AUTOSAR XML (schema 00046)
package /ComponentTypes
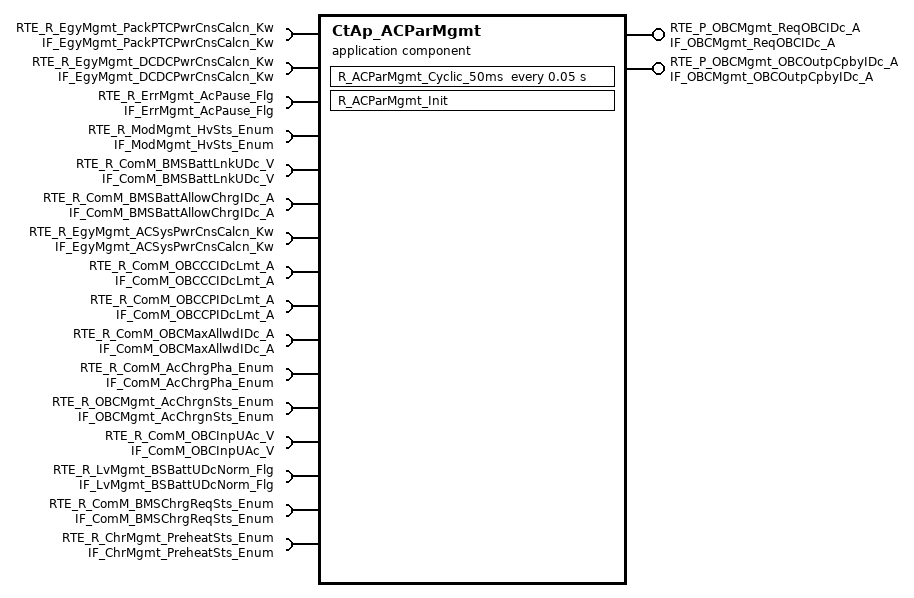
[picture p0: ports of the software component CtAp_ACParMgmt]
  application sw component type CtAp_ACParMgmt
    4 x require port:
      RTE_R_EgyMgmt_PackPTCPwrCnsCalcn_Kw: nonqueued-receiver-com-spec{data-element=tec_EgyMgmt_PackPTCPwrCnsCalcn_Kw, filter=data-filter-type=ALWAYS, init-value=0}, required-interface=IF_EgyMgmt_PackPTCPwrCnsCalcn_Kw
      RTE_R_EgyMgmt_DCDCPwrCnsCalcn_Kw: nonqueued-receiver-com-spec{data-element=tec_EgyMgmt_DCDCPwrCnsCalcn_Kw, filter=data-filter-type=ALWAYS, init-value=0}, required-interface=IF_EgyMgmt_DCDCPwrCnsCalcn_Kw
      RTE_R_ErrMgmt_AcPause_Flg: nonqueued-receiver-com-spec{data-element=tec_ErrMgmt_AcPause_Flg, filter=data-filter-type=ALWAYS, init-value=0}, required-interface=IF_ErrMgmt_AcPause_Flg
      RTE_R_ModMgmt_HvSts_Enum: nonqueued-receiver-com-spec{data-element=tec_ModMgmt_HvSts_Enum, filter=data-filter-type=ALWAYS, init-value=0}, required-interface=IF_ModMgmt_HvSts_Enum
    provide port RTE_P_OBCMgmt_ReqOBCIDc_A: nonqueued-sender-com-spec{data-element=tec_OBCMgmt_ReqOBCIDc_A, init-value=0}, provided-interface=IF_OBCMgmt_ReqOBCIDc_A
    6 x require port:
      RTE_R_ComM_BMSBattLnkUDc_V: nonqueued-receiver-com-spec{data-element=tec_ComM_BMSBattLnkUDc_V, filter=data-filter-type=ALWAYS, init-value=0}, required-interface=IF_ComM_BMSBattLnkUDc_V
      RTE_R_ComM_BMSBattAllowChrgIDc_A: nonqueued-receiver-com-spec{data-element=tec_ComM_BMSBattAllowChrgIDc_A, filter=data-filter-type=ALWAYS, init-value=0}, required-interface=IF_ComM_BMSBattAllowChrgIDc_A
      RTE_R_EgyMgmt_ACSysPwrCnsCalcn_Kw: nonqueued-receiver-com-spec{data-element=tec_EgyMgmt_ACSysPwrCnsCalcn_Kw, filter=data-filter-type=ALWAYS, init-value=0}, required-interface=IF_EgyMgmt_ACSysPwrCnsCalcn_Kw
      RTE_R_ComM_OBCCCIDcLmt_A: nonqueued-receiver-com-spec{data-element=tec_ComM_OBCCCIDcLmt_A, filter=data-filter-type=ALWAYS, init-value=0}, required-interface=IF_ComM_OBCCCIDcLmt_A
      RTE_R_ComM_OBCCPIDcLmt_A: nonqueued-receiver-com-spec{data-element=tec_ComM_OBCCPIDcLmt_A, filter=data-filter-type=ALWAYS, init-value=0}, required-interface=IF_ComM_OBCCPIDcLmt_A
      RTE_R_ComM_OBCMaxAllwdIDc_A: nonqueued-receiver-com-spec{data-element=tec_ComM_OBCMaxAllwdIDc_A, filter=data-filter-type=ALWAYS, init-value=0}, required-interface=IF_ComM_OBCMaxAllwdIDc_A
    provide port RTE_P_OBCMgmt_OBCOutpCpbyIDc_A: nonqueued-sender-com-spec{data-element=tec_OBCMgmt_OBCOutpCpbyIDc_A, init-value=0}, provided-interface=IF_OBCMgmt_OBCOutpCpbyIDc_A
    6 x require port:
      RTE_R_ComM_AcChrgPha_Enum: nonqueued-receiver-com-spec{data-element=tec_ComM_AcChrgPha_Enum, filter=data-filter-type=ALWAYS, init-value=0}, required-interface=IF_ComM_AcChrgPha_Enum
      RTE_R_OBCMgmt_AcChrgnSts_Enum: nonqueued-receiver-com-spec{data-element=tec_OBCMgmt_AcChrgnSts_Enum, filter=data-filter-type=ALWAYS, init-value=0}, required-interface=IF_OBCMgmt_AcChrgnSts_Enum
      RTE_R_ComM_OBCInpUAc_V: nonqueued-receiver-com-spec{data-element=tec_ComM_OBCInpUAc_V, filter=data-filter-type=ALWAYS, init-value=0}, required-interface=IF_ComM_OBCInpUAc_V
      RTE_R_LvMgmt_BSBattUDcNorm_Flg: nonqueued-receiver-com-spec{data-element=tec_LvMgmt_BSBattUDcNorm_Flg, filter=data-filter-type=ALWAYS, init-value=0}, required-interface=IF_LvMgmt_BSBattUDcNorm_Flg
      RTE_R_ComM_BMSChrgReqSts_Enum: nonqueued-receiver-com-spec{data-element=tec_ComM_BMSChrgReqSts_Enum, filter=data-filter-type=ALWAYS, init-value=0}, required-interface=IF_ComM_BMSChrgReqSts_Enum
      RTE_R_ChrMgmt_PreheatSts_Enum: nonqueued-receiver-com-spec{data-element=tec_ChrMgmt_PreheatSts_Enum, filter=data-filter-type=ALWAYS, init-value=0}, required-interface=IF_ChrMgmt_PreheatSts_Enum
    behavior CtAp_ACParMgmt_InternalBehavior
      timing event TMT_R_ACParMgmt_Cyclic_50ms: start-on-event=R_ACParMgmt_Cyclic_50ms, period=0.05
      init event CtAp_ACParMgmt_InitEvent: start-on-event=R_ACParMgmt_Init
      runnable R_ACParMgmt_Cyclic_50ms
        data-receive-point-by-arguments:
          16 x access:
            REC_RTE_R_ComM_AcChrgPha_Enum_tec_ComM_AcChrgPha_Enum: accessed-variable=RTE_R_ComM_AcChrgPha_Enum.tec_ComM_AcChrgPha_Enum
            REC_RTE_R_ComM_BMSBattAllowChrgIDc_A_tec_ComM_BMSBattAllowChrgIDc_A: accessed-variable=RTE_R_ComM_BMSBattAllowChrgIDc_A.tec_ComM_BMSBattAllowChrgIDc_A
            REC_RTE_R_ComM_BMSBattLnkUDc_V_tec_ComM_BMSBattLnkUDc_V: accessed-variable=RTE_R_ComM_BMSBattLnkUDc_V.tec_ComM_BMSBattLnkUDc_V
            REC_RTE_R_ComM_OBCCCIDcLmt_A_tec_ComM_OBCCCIDcLmt_A: accessed-variable=RTE_R_ComM_OBCCCIDcLmt_A.tec_ComM_OBCCCIDcLmt_A
            REC_RTE_R_ComM_OBCCPIDcLmt_A_tec_ComM_OBCCPIDcLmt_A: accessed-variable=RTE_R_ComM_OBCCPIDcLmt_A.tec_ComM_OBCCPIDcLmt_A
            REC_RTE_R_ComM_OBCInpUAc_V_tec_ComM_OBCInpUAc_V: accessed-variable=RTE_R_ComM_OBCInpUAc_V.tec_ComM_OBCInpUAc_V
            REC_RTE_R_ComM_OBCMaxAllwdIDc_A_tec_ComM_OBCMaxAllwdIDc_A: accessed-variable=RTE_R_ComM_OBCMaxAllwdIDc_A.tec_ComM_OBCMaxAllwdIDc_A
            REC_RTE_R_EgyMgmt_ACSysPwrCnsCalcn_Kw_tec_EgyMgmt_ACSysPwrCnsCalcn_Kw: accessed-variable=RTE_R_EgyMgmt_ACSysPwrCnsCalcn_Kw.tec_EgyMgmt_ACSysPwrCnsCalcn_Kw
            REC_RTE_R_EgyMgmt_DCDCPwrCnsCalcn_Kw_tec_EgyMgmt_DCDCPwrCnsCalcn_Kw: accessed-variable=RTE_R_EgyMgmt_DCDCPwrCnsCalcn_Kw.tec_EgyMgmt_DCDCPwrCnsCalcn_Kw
            REC_RTE_R_EgyMgmt_PackPTCPwrCnsCalcn_Kw_tec_EgyMgmt_PackPTCPwrCnsCalcn_Kw: accessed-variable=RTE_R_EgyMgmt_PackPTCPwrCnsCalcn_Kw.tec_EgyMgmt_PackPTCPwrCnsCalcn_Kw
            REC_RTE_R_ErrMgmt_AcPause_Flg_tec_ErrMgmt_AcPause_Flg: accessed-variable=RTE_R_ErrMgmt_AcPause_Flg.tec_ErrMgmt_AcPause_Flg
            REC_RTE_R_ModMgmt_HvSts_Enum_tec_ModMgmt_HvSts_Enum: accessed-variable=RTE_R_ModMgmt_HvSts_Enum.tec_ModMgmt_HvSts_Enum
            REC_RTE_R_OBCMgmt_AcChrgnSts_Enum_tec_OBCMgmt_AcChrgnSts_Enum: accessed-variable=RTE_R_OBCMgmt_AcChrgnSts_Enum.tec_OBCMgmt_AcChrgnSts_Enum
            REC_RTE_R_ComM_BMSChrgReqSts_Enum_tec_ComM_BMSChrgReqSts_Enum: accessed-variable=RTE_R_ComM_BMSChrgReqSts_Enum.tec_ComM_BMSChrgReqSts_Enum
            REC_RTE_R_LvMgmt_BSBattUDcNorm_Flg_tec_LvMgmt_BSBattUDcNorm_Flg: accessed-variable=RTE_R_LvMgmt_BSBattUDcNorm_Flg.tec_LvMgmt_BSBattUDcNorm_Flg
            REC_RTE_R_ChrMgmt_PreheatSts_Enum_tec_ChrMgmt_PreheatSts_Enum: accessed-variable=RTE_R_ChrMgmt_PreheatSts_Enum.tec_ChrMgmt_PreheatSts_Enum
        data-send-points:
          access SEND_RTE_P_OBCMgmt_OBCOutpCpbyIDc_A_tec_OBCMgmt_OBCOutpCpbyIDc_A: accessed-variable=RTE_P_OBCMgmt_OBCOutpCpbyIDc_A.tec_OBCMgmt_OBCOutpCpbyIDc_A
          access SEND_RTE_P_OBCMgmt_ReqOBCIDc_A_tec_OBCMgmt_ReqOBCIDc_A: accessed-variable=RTE_P_OBCMgmt_ReqOBCIDc_A.tec_OBCMgmt_ReqOBCIDc_A
      runnable R_ACParMgmt_Init
  swc implementation CtAp_ACParMgmt_Implementation: behavior=CtAp_ACParMgmt_InternalBehavior
